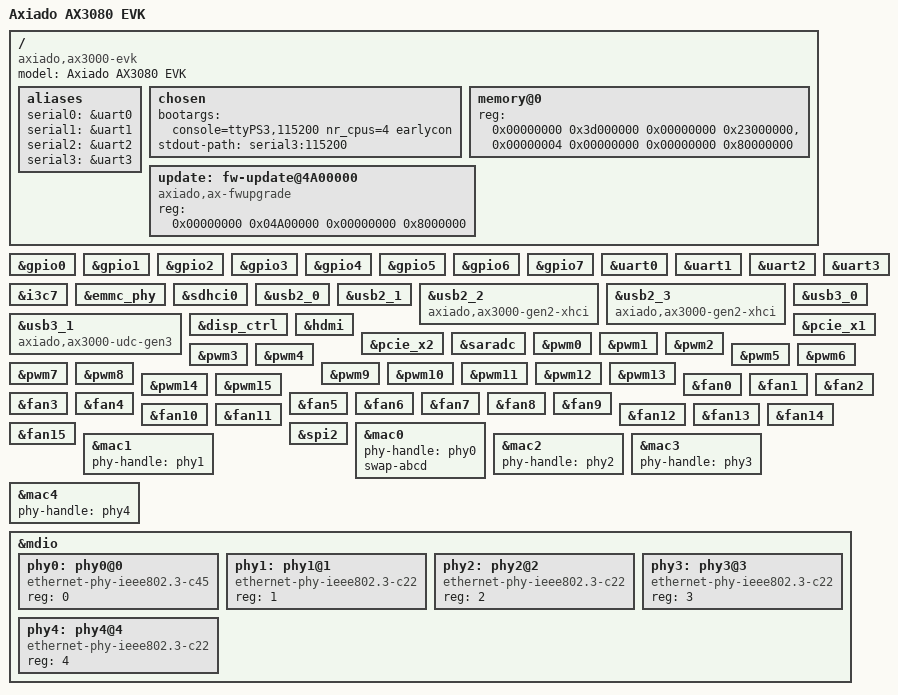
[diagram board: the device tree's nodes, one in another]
// SPDX-License-Identifier: GPL-2.0+
/*
 * DTS file for Axiado AX3080 SoC based EVK
 */

/dts-v1/;

#include "ax3000.dtsi"
#include "ax3000-net-mod.dtsi"

/ {
	model = "Axiado AX3080 EVK";
	compatible = "axiado,ax3000-evk", "axiado,ax3000";
	#address-cells = <2>;
	#size-cells = <2>;

	aliases {
		serial0 = &uart0;
		serial1 = &uart1;
		serial2 = &uart2;
		serial3 = &uart3;
	};

	chosen {
		bootargs = "console=ttyPS3,115200 nr_cpus=4 earlycon";
		stdout-path = "serial3:115200";
	};

	memory@0 {
		device_type = "memory";
		/* Cortex-A53 will use following memory map */
		reg = <0x00000000 0x3d000000 0x00000000 0x23000000>,
		      <0x00000004 0x00000000 0x00000000 0x80000000>;
	};

	update: fw-update@4A00000 {
		compatible = "axiado,ax-fwupgrade";
		/* Reserved memory space for the firmware upgrade */
		reg = <0x00000000 0x04A00000 0x00000000 0x8000000>;
		status = "okay";
	};
};

/* GPIO bank 0 - 7 */
&gpio0 {
	status = "okay";
};

&gpio1 {
	status = "okay";
};

&gpio2 {
	status = "okay";
};

&gpio3 {
	status = "okay";
};

&gpio4 {
	status = "okay";
};

&gpio5 {
	status = "okay";
};

&gpio6 {
	status = "okay";
};

&gpio7 {
	status = "okay";
};


&uart0 {
	status = "okay";
};

&uart1 {
	status = "okay";
};

&uart2 {
	status = "okay";
};

&uart3 {
	status = "okay";
};

&i3c7 {
    status = "okay";
};

&emmc_phy {
	status = "okay";
};

&sdhci0 {
	status = "okay";
};

&usb2_0 {
	status = "okay";
};

&usb2_1 {
	status = "okay";
};

&usb2_2 {
	compatible = "axiado,ax3000-gen2-xhci", "generic-xhci";
	status = "okay";
};

&usb2_3 {
	compatible = "axiado,ax3000-gen2-xhci", "generic-xhci";
	status = "okay";
};

&usb3_0 {
	status = "okay";
};

&usb3_1 {
	compatible = "axiado,ax3000-udc-gen3";
	reg-names = "mmio";
	status = "okay";
};

&disp_ctrl {
	status = "okay";
};

&hdmi {
	status = "okay";
};

&pcie_x1 {
	status = "okay";
};

&pcie_x2 {
	status = "okay";
};

&saradc {
	status = "okay";
};

&pwm0 {
	status = "okay";
};

&pwm1 {
	status = "okay";
};

&pwm2 {
	status = "okay";
};

&pwm3 {
	status = "okay";
};

&pwm4 {
	status = "okay";
};

&pwm5 {
	status = "okay";
};

&pwm6 {
	status = "okay";
};

&pwm7 {
	status = "okay";
};

&pwm8 {
	status = "okay";
};

&pwm9 {
	status = "okay";
};

&pwm10 {
	status = "okay";
};

&pwm11 {
	status = "okay";
};

&pwm12 {
	status = "okay";
};

&pwm13 {
	status = "okay";
};

&pwm14 {
	status = "okay";
};

&pwm15 {
	status = "okay";
};

&fan0 {
	status = "okay";
};

&fan1{
	status = "okay";
};

&fan2 {
	status = "okay";
};

&fan3 {
	status = "okay";
};

&fan4 {
	status = "okay";
};

&fan5 {
	status = "okay";
};

&fan6 {
	status = "okay";
};

&fan7 {
	status = "okay";
};

&fan8 {
	status = "okay";
};

&fan9 {
	status = "okay";
};

&fan10 {
	status = "okay";
};

&fan11 {
	status = "okay";
};

&fan12 {
	status = "okay";
};

&fan13 {
	status = "okay";
};

&fan14 {
	status = "okay";
};

&fan15 {
	status = "okay";
};

&spi2 {
	status = "okay";
};

&mac0 {
	phy-handle = <&phy0>;
	swap-abcd;
	status = "okay";
};

&mac1 {
	phy-handle = <&phy1>;
	status = "okay";
};

&mac2 {
	phy-handle = <&phy2>;
	status = "okay";
};

&mac3 {
	phy-handle = <&phy3>;
	status = "okay";
};

&mac4 {
	phy-handle = <&phy4>;
	status = "okay";
};

&mdio {
	phy0: phy0@0 {
		reg = <0>;
		compatible = "ethernet-phy-ieee802.3-c45";
		status = "okay";
	};
	phy1: phy1@1 {
		reg = <1>;
		compatible = "ethernet-phy-ieee802.3-c22";
		status = "okay";
	};
	phy2: phy2@2 {
		reg = <2>;
		compatible = "ethernet-phy-ieee802.3-c22";
		status = "okay";
	};
	phy3: phy3@3 {
		reg = <3>;
		compatible = "ethernet-phy-ieee802.3-c22";
		status = "okay";
	};
	phy4: phy4@4 {
		reg = <4>;
		compatible = "ethernet-phy-ieee802.3-c22";
		status = "okay";
	};
};
